# cslr_i2c_001 register map
Vendor: Texas Instruments
Peripheral module from a debugger description file.
Registers are 16-bit, access not given, reset 0x0 unless marked. A register's access mark holds for its fields unless they carry their own. Offsets are as the file gives them; lines under a group give offsets from that group; [hi:lo] are bit positions; {n}, {i} and the like mark numbered series; 'fields as' and 'values as' point back to an identical list; <NAME> marks a mode.

## I2C
0x00 ICOAR — I2C Own Address Register
  [9:0] OADDR rw — Own address
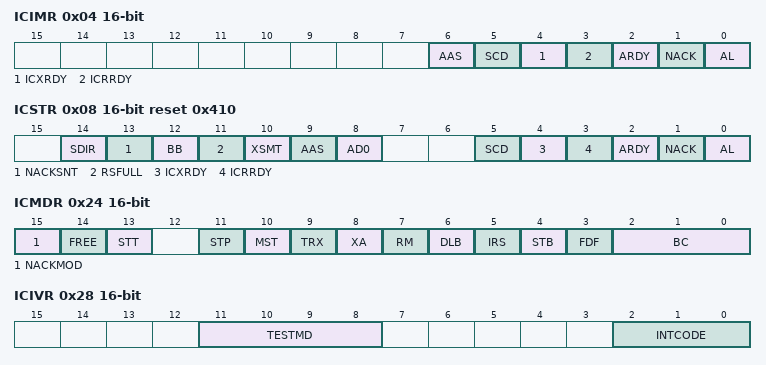
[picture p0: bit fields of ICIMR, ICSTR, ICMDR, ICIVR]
0x04 ICIMR — I2C Interrupt Mask Register
  [all] fields
    0=DISABLE (Mask interrupt); 1=ENABLE (Unmask interrupt)
  [6] AAS rw — Address As Slave interrupt mask bit
  [5] SCD rw — Stop Condition Detect mask bit
  [4] ICXRDY rw — Trasmit Data Ready interrupt mask bit
  [3] ICRRDY rw — Receive Data Ready interrupt mask bit
  [2] ARDY rw — Register access ready interrupt mask bit
  [1] NACK rw — No Acknowledgement interrupt mask bit
  [0] AL rw — Arbitration Lost interrupt mask bit
0x08 ICSTR reset 0x410 — I2C Interrupt Status Register
  [14] SDIR rw — Slave direction This bit is clear to '0' indicating the I2C is a master transmitter/receiver or a slave receiver. This bit is also clear by STOP condition or START condition. It is set to '1' when the I2C slave is a transmitter. In DLB mode (which the configuration should be master-transmitter slave-receiver), this bit is clear to '0'. Writing a '1' to this bit to clear it.
  [13] NACKSNT rw — A No Acknowledge is sent due to NACKMOD is set to a '1'. NACKSNT =0: A No Acknowledge is not sent. NACKSNT =1: A No Acknowledge is sent. Writing a '1' to this bit to clear it.
  [12] BB ro — Bus Busy. This bit indicates the state of the serial bus. BB=0: The bus is free. BB=1: The bus is occupied. On reception of a 'start' condition, the device sets BB to 1. This bit is also set if SCL low state and IRS is '0'. BB is clear to 0 after reception of a 'stop' condition. In the 'master' mode, BB is controlled by the software. When BB=1, and STT is set to a 1, a restart condition is generated.
  [11] RSFULL ro — Receive shift full. This bit indicates whether the receiver has experienced overrun. Overrun occurs when the receive shift register (ICRSR) is full and ICDRR has not been read since the ICRSR-to-ICDRR transfer. The FSM is holding for ICDRR read access. RSFULL is clear when reading the ICDRR, or resetting the I2C (IRS_=0), or resetting the device. RSFULL is set to '1' when the I2C has recognized an overrun. The contents of ICDRR are NOT lost in this case. RSFULL is clear as a result of reading the ICDRR.
  [10] XSMT rw — Transmit shift empty not. This bit indicates whether the transmitter has experienced underflow. Underflow occurs when the transmit shift register (ICXSR) is empty and ICDXR has not been loaded. The FSM is holding for ICDXR write access. XSMT_ is clear when underflow has occurred. Resetting the I2C (IRS_=0) or the device sets it to a '1'. XSMT_ is set to '1' as a result of writing to ICDXR.
  [9] AAS ro — Address As Slave. This bit is set to 1 by the device when it has recognized its own slave address or an address of all (8) zeros. The AAS bit is reset by restart or stop condition. The device remains selected until the 'stop' condition.
  [8] AD0 ro — Address Zero Status: This bit is set to 1 by device if it detects the address of all (8) zeros (i.e. general call). The AD0 bit is reset to 0 (default value) when a 'start' or 'stop' condition is detected.
  [5] SCD rw — Stop Condition Detection bit SCD is set when the I2C sends or receives STOP condition. This bit is cleared by reading ICIVR (as 110) or writing '1' to itself.
  [4] ICXRDY rw — Transmit Data Ready interrupt flag bit. ICXRDY is set to '1' when the LSB transmitted data bit has been shifted out of the ICDXR. ICRXDY is clear to '0' when the ICDXR is written. This bit can also be polled by the DSP to write a new transmitted data into the ICDXR. Write '1' or DXR Write will clear it.
  [3] ICRRDY rw — Receive Data Ready interrupt flag bit. ICRRDY is set to '1' when the LSB received data bit has been shifted into the ICDRR. ICRRDY is clear to '0' when the ICDRR is read. This bit can also be polled by the DSP to read the received data in the ICDRR. Write '1' or DRR Read will clear it.
  [2] ARDY rw — Register-access-ready interrupt flag bit. ARDY is generated by the hardware, if the I2C is in the master mode, when the previously programmed data and command has been performed and status bit has been updated. This flag is used by the DSP to let it knows that the I2C registers are ready to be accessed again. When RM=0, ARDY is set when the internal data count is passed 0 if STP register bit has not been set. When RM=1, ARDY is set at each byte end. Write '1' will clear it.
  [1] NACK rw — No-Acknowledgement interrupt flag bit. The No Acknowledge flag bit is set when the hardware detects no acknowledge has been received. Write '1' or Read the IVR will clear it.
  [0] AL rw — Arbitration Lost interrupt flag bit The Arbitration Lost flag bit is set to 1 when the device in the 'master transmitter' mode senses it has lost an arbitration when two or more transmitters start a transmission almost simultaneously or when the I2C attempts to start a transfer while BB (bus busy) is 1. When this is set to 1 due to arbitration lost, the MST/STP bits are clear, the I2C becomes a slave receiver. Write '1' or Read the IVR will clear it.
0x0C ICCLKL rw — I2C Clock Divider Low Register
  [15:0] ICCL — Low time I2C SCL Clock Division Factor. They are used to divide down the master clock to create the SCL low time transition frequency. This register must be configured while the I2C is still in reset (IRS=0)
0x10 ICCLKH rw — I2C Clock Divider High Register
  [15:0] ICCH — High time I2C SCL Clock Division Factor. They are used to divide down the master clock to create the SCL high time transition frequency. This register must be configured while the I2C is still in reset (IRS=0)
0x14 ICCNT rw — I2C Data Count Register
  [15:0] ICDC — Data count. This data count register is used to generate a Stop condition if a Stop condition is specified (STP=1). ICCNT=1, data count is 1 :::::::::::::::::::::::::::::::::::::::::::: ICCNT=0FFFFh, data count is 65535 ICCNT=0,data counter is 65536 Note that ICCNT is a don't care when RM is set to 1.
0x18 ICDRR — I2C Data Receive Register
  [7:0] D ro — Receive data
0x1C ICSAR reset 0x3FF — I2C Slave Address Register
  [9:0] SADDR rw — Slave address. Use in both 7- and 10-bit address mode
0x20 ICDXR — I2C Data Transmit Register
  [7:0] D rw — Transmit data
0x24 ICMDR — I2C Mode Register
  [15] NACKMOD rw — No Acknowledge (NACK) mode. This bit is used to send an Acknowledge (ACK) or a No Acknowledge (NACK) to the transmitter. This bit is only applicable when the I2C is in receiver mode. In master receiver mode, when the internal data count counter decrements to zero, the I2C sends a NACK. The master receiver I2C finishes a transfer when it sends a NACK. The I2C ignores ICCNT when NACKMOD is '1'. The NACKMOD bit should be set before the rising edge of the last data bit (bit 8) if a NACK must be sent and this bit is cleared once a NACK has been sent. NACKMOD=0, the I2C sends an ACK to the transmitter during the acknowledge cycle. NACKMOD=1, the I2C sends a NACK to the transmitter during the acknowledge cycle.
  [14] FREE rw — Free Running. This bit is used to determine the state of the I2C when a breakpoint is encountered in the HLL debugger. FREE=0: (default) Stops immediately if SCL is low and keep driving SCL low whether I2C is master transmitter/receiver. If SCL is high, I2C waits until SCL becomes low and then stops. If the I2C is a slave, it will stop when the transmission/receiving completes. FREE=1: The I2C runs free.
  [13] STT rw — Start Condition (Master only mode). This bit can be set to a '1' by the DSP to generate a Start condition. In master mode, when setting Start to '1' generates a Start condition. It is reset to '0' by the hardware after the Start condition has been generated. The Start/Stop bits can be configured to generate different transfer formats. Note that the STT and STP can be used to terminate the repeat mode. STT, STP, Conditions, Bus Activities (In order below:) 1, 0, Start, S-A-D 0, 1, Stop, P 1, 1, Start-Stop (ICCNT= n), S-A-D..(n)..D-P 1, 0, Start (ICCNT= n), S-A-D..(n)..D
  [11] STP rw — Stop Condition (Master mode only). This bit can be set to a '1' by the DSP to generate a Stop condition. It is reset to '0' by the hardware after the Stop condition has been generated. The Stop condition is generated when ICCNT passes 0.
  [10] MST rw — Master MST=0: The I 2 C peripheral is in the 'slave' mode and clock is received from the 'master' device. MST=1: The I 2 C peripheral is in the 'master' mode and it generates the clock. This bit is clear when the transfer completed.
  [9] TRX rw — Transmitter. TRX=0: The I 2 C is in the 'receiver' mode and data on data line SDA is shifted into the data register ICDRR. TRX=1: The I 2 C is in the 'transmitter' mode and the data in ICDXR is shifted out on data line SDA. The operating modes are defined as follows. MST, TRX, Operating Modes (In order below) 0, x, 'slave receiver' 0, x, 'slave transmitter' 1, 0, 'master receiver' 1, 1, 'master transmitter'
  [8] XA rw — Expanded Address (both Master and Slave mode). XA=0: (default) 7-bit address mode (normal address mode). XA=1: 10-bit address mode (expanded address mode)
  [7] RM rw — Repeat Mode. This bit is set to a '1' by the DSP to put the I2C in the repeat mode. In this mode, data is continuously transmitted out of the ICDXR until the STP bit is set to '1' regardless of ICCNT value. This bit is don't care if the I2C is configured in slave mode. RM, STT, STP, Conditions, Bus activities, Mode (in order below) 0, 0, 0, Idle, None, NA 0, 0, 1, Stop, P, NA 0, 1, 0, (Re)Start, S-A-D..(n)..D, Repeat n 0, 1, 1, (Re)Start-Stop, S-A-D..(n)..D-P, Repeat n 1, 0, 0, Idle, None, NA 1, 0, 1, Stop, P, NA 1, 1, 0, (Re)Start, S-A-D-D-D..., Continuous 1, 1, 1, Reserved, None, NA
  [6] DLB rw — Digital Loop Back (in master transmit mode only). This bit is set to a '1' by the DSP to put the I2C in the loop back mode. In this mode, data transmitted out of the ICDXR will be received in the ICDRR after ((DSP freq/I2C freq)*8) DSP cycles via an internal path. The address of the ICOAR is output on SDA.
  [5] IRS rw — I2C Reset Not. This can be set to a '0' by the DSP to put the I2C in reset or to a '1' to take the I2C out of reset. When this bit is reset to 0, all status bits in ICSTR are set to default values. Note that if this bit is reset during a transfer, it can cause the I2C bus hang (SDA and SCL are tri-stated).
  [4] STB rw — Start Byte (Master only mode). The Start Byte mode bit is set to 1 by the DSP to configure the I2C in Start byte mode, the I2C sends 00000001 regardless ICSAR value. Refer to the Philip I2C spec for more details.
  [3] FDF rw — Free Data Format (both Master and Slave modes). This bit can be set to '1' by the DSP to configure the I2C in Free Data Format mode FDF MST TRX Operating mode (In order below) 0 0 x Slave in non FDF mode 0 1 0 Master receive in non FDF mode 0 1 1 Master transmit in non FDF mode 1 0 0 Slave receiver in FDF mode 1 0 1 Slave transmitter in FDF mode 1 1 0 Master receiver in FDF mode 1 1 1 Master transmitter in FDF mode
  [2:0] BC rw — Bit Count. Bit Count defines the number of bits starting from the lsb (excluding the acknowledge bit) of the next byte which are yet to be received or transmitted. BC, Bits/byte in FDF, Bits/byte w/ ACK (In order below) 001, NA (reserved), NA (reserved) 010, 2, 3 011, 3, 4 100, 4, 5 101, 5, 6 110, 6, 7 111, 7, 8 000, 8, 9
0x28 ICIVR — I2C Interrupt Vector Register
  [11:8] TESTMD rw — Reserved for internal testing
  [2:0] INTCODE ro — Interrupt code. The binary-coded-interrupt vector indicates which interrupt has occurred. Reading the ICIVR clears the interrupt flag; if other interrupts are pending, a new interrupt is generated. If there are more than one interrupt flag, reading the ICIVR clears the highest priority interrupt flag. Note that users must read (clear) the IVR before doing another start otherwise the IVR could contain incorrect (old interrupt flags) value.
    0=NONE (No interrupt occurred); 1=AL (Arbitration Lost interrupt occurred (Highest Priority)); 2=NACK (No Acknowledge interrupt occurred); 3=RAR (Register Access Ready interrupt occurred); 4=RDR (Receive Data Ready interrupt occurred); 5=TDR (Transmit Data Ready interrupt occurred); 6=SCD (Stop Condition Detect interrupt occurred); 7=AAS (Address As Slave interrupt occurred (Lowest Priority))
0x2C ICEMDR reset 0x1 — I2C Extended Mode Register
  [0] BCM rw — Backward Compatibility Mode This bit affects the I2C interrupt behavior.
0x30 ICPSC — I2C Prescaler Register
  [7:0] IPSC rw — 8-bit prescaler to divide the system clock down to 4/8/12Mhz clock and used by the I2C module. This register must be initialized while the I2C is still in reset (IRS_=0). The value takes effect on the rising edge of IRS_.
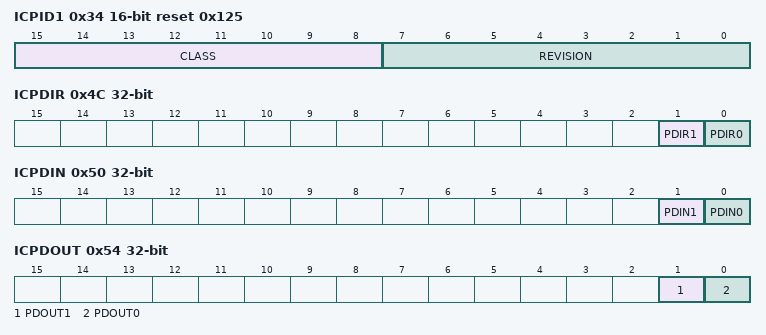
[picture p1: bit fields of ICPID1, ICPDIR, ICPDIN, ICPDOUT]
0x34 ICPID1 ro reset 0x125 — I2C Peripheral ID Register 1
  [15:8] CLASS — Identifies the class of peripheral. This value should be 0x01
  [7:0] REVISION — Identifies the revision level of the I2C. This value should be 0x25, and be incremented each time the design is revised.
0x38 ICPID2 reset 0x5 — I2C Peripheral ID Register 2
  [7:0] TYPE ro — Identifies the type of peripheral. This value should be 0x05
0x48 ICPFUNC 32-bit — I2C Pin Function Register
  [0] PFUNC rw — Controls the function of the I2C SCL and SDA pins 0 = Pins function as SCL and SDA 1 = Pins functions as GPIO Note: No hardware protection is required to disable I2C function when the PFUNC[0] and IRS_ bits are both set to one. When PFUNC[0] is '1' (GPIO mode), the sub-module which controls the I2C function receives the value '1' for SCL and SDA. IRS_ can be set to '1' regardless of PFUNC[0], and the I2C function works whenever the IRS_ bit is '1'. The user is expected to hold I2C in reset via IRS_ bit when changing to/from GPIO mode via the PFUNC[0] bit.
0x4C ICPDIR 32-bit — I2C Pin Direction Register
  [1] PDIR1 rw — Controls the direction of the I2C SDA pin when configured as GPIO.
    0=IN (SDA pin functions as input); 1=OUT (SDA pin functions as output)
  [0] PDIR0 rw — Controls the direction of the I2C SCL pin when configured as GPIO.
    0=IN (SCL pin functions as input); 1=OUT (SCL pin functions as output)
0x50 ICPDIN 32-bit — I2C Pin Data In Register
  [1] PDIN1 ro — Indicates the logic level present on the SDA pin
    0=LOW (Logic Low present at SDA pin); 1=HIGH (Logic High present at SDA pin)
  [0] PDIN0 ro — Indicates the logic level present on the SCL pin
    0=LOW (Logic Low present at SCL pin); 1=HIGH (Logic High present at SCL pin)
0x54 ICPDOUT 32-bit — I2C Pin Data Out Register
  [1] PDOUT1 rw — Controls the level driven on the SDA pin when configured as GPIO output Read: Reads return register values, not GPIO pin levels Write: SDA pin driven accordingly
    0=LOW (SDA pin driven low); 1=HIGH (SDA pin driven high)
  [0] PDOUT0 rw — Controls the level driven on the SCL pin when configured as GPIO output Read: Reads return register values, not GPIO pin levels Write: SCL pin driven accordingly
    0=LOW (SCL pin driven low); 1=HIGH (SCL pin driven high)
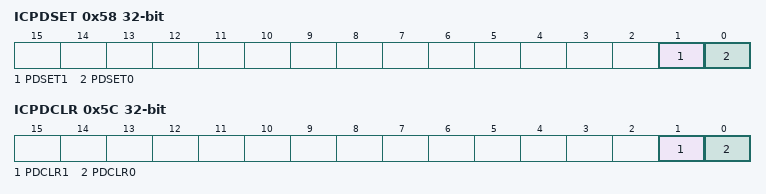
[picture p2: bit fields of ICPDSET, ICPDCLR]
0x58 ICPDSET 32-bit — I2C Pin Data Set Register
  [1] PDSET1 rw — Used to set PDOUT[1] bit which corresponds to the SDA GPIO pin.
    0=NONE (No effect); 1=SET (Set to Logic High)
  [0] PDSET0 rw — Used to set PDOUT[0] bit which corresponds to the SCL GPIO pin.
    0=NONE (No effect); 1=SET (Set to Logic High)
0x5C ICPDCLR 32-bit — I2C Pin Data Clear Register
  [1] PDCLR1 wo — Used to clear PDOUT[1] bit which corresponds to the SDA GPIO pin.
    0=NONE (No effect); 1=RESET (Clear to Logic Low)
  [0] PDCLR0 wo — Used to clear PDOUT[0] bit which corresponds to the SCL GPIO pin.
    0=NONE (No effect); 1=RESET (Clear to Logic Low)
